# STM32H7P4 register map
File version: 0.1
CPU: CM7 r1p2, little endian, MPU, FPU, 4 interrupt priority bits
Registers are 32-bit, read-write, reset 0x0 unless marked. A register's access mark holds for its fields unless they carry their own. Offsets are from the block's base; [hi:lo] are bit positions.

## ADCC12 — Analog-to-digital converters
Base 0x48026300
Same registers: ADCC34 0x48026700
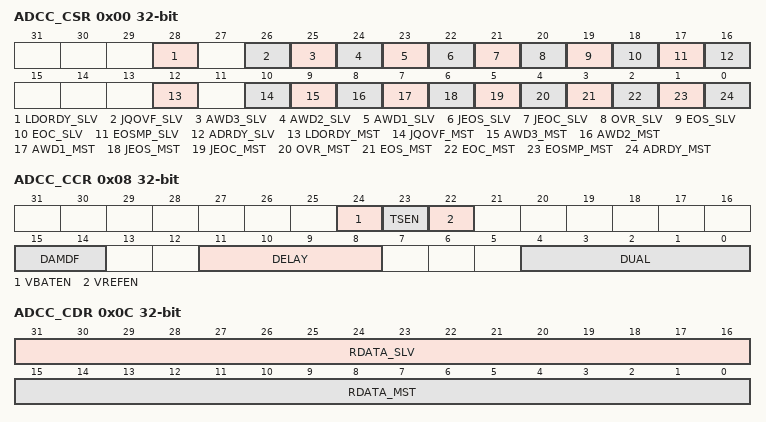
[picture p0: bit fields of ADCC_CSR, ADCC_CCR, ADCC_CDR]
0x00 ADCC_CSR ro — ADC common status register
  [28] LDORDY_SLV — ADC internal voltage regulator flag of the slave ADC
  [26] JQOVF_SLV — Injected context queue overflow flag of the slave ADC
  [25] AWD3_SLV — Analog watchdog 3 flag of the slave ADC
  [24] AWD2_SLV — Analog watchdog 2 flag of the slave ADC
  [23] AWD1_SLV — Analog watchdog 1 flag of the slave ADC
  [22] JEOS_SLV — End of injected sequence flag of the slave ADC
  [21] JEOC_SLV — End of injected conversion flag of the slave ADC
  [20] OVR_SLV — Overrun flag of the slave ADC
  [19] EOS_SLV — End of regular sequence flag of the slave ADC. This bit is a copy of the EOS bit in the corresponding ADC_ISR register.
  [18] EOC_SLV — End of regular conversion of the slave ADC
  [17] EOSMP_SLV — End of sampling phase flag of the slave ADC
  [16] ADRDY_SLV — Slave ADC ready
  [12] LDORDY_MST — ADC internal voltage regulator flag of the master ADC
  [10] JQOVF_MST — Injected context queue overflow flag of the master ADC
  [9] AWD3_MST — Analog watchdog 3 flag of the master ADC
  [8] AWD2_MST — Analog watchdog 2 flag of the master ADC
  [7] AWD1_MST — Analog watchdog 1 flag of the master ADC
  [6] JEOS_MST — End of injected sequence flag of the master ADC
  [5] JEOC_MST — End of injected conversion flag of the master ADC
  [4] OVR_MST — Overrun flag of the master ADC
  [3] EOS_MST — End of regular sequence flag of the master ADC
  [2] EOC_MST — End of regular conversion of the master ADC
  [1] EOSMP_MST — End of Sampling phase flag of the master ADC
  [0] ADRDY_MST — Master ADC ready
0x08 ADCC_CCR — ADC common control register
  [24] VBATEN — VBAT enable
    0=Vless thansub>BATless than/sub> channel disabled; 1=Vless thansub>BATless than/sub> channel enabled
  [23] TSEN — Temperature sensor voltage enable
    0=Temperature sensor channel disabled; 1=Temperature sensor channel enabled
  [22] VREFEN — Vless thansub>REFINTless than/sub> enable
    0=Vless thansub>REFINTless than/sub> channel disabled; 1=Vless thansub>REFINTless than/sub> channel enabled
  [15:14] DAMDF — Dual ADC mode data format
    0=Dual ADC mode without data packing (ADCC_CDR and ADCC_CDR2 registers not used); 2=Data formatting mode for any data width (ADCC_CDR data register is used when the data width is less than 16 bits, otherwise ADCC_CDR2 register is used); 3=Data formatting mode for data width lower that 8 bits (ADCC_CDR data register is used)
  [11:8] DELAY — Delay between two sampling phases
  [4:0] DUAL — Dual ADC mode selection
    0=Independent mode; 1=Combined regular simultaneous + Injected simultaneous mode; 2=Combined regular simultaneous + Alternate trigger mode; 3=Combined interleaved mode + Injected simultaneous mode; 5=Injected simultaneous mode only; 6=Regular simultaneous mode only; 7=Interleaved mode only; 9=Alternate trigger mode only
0x0C ADCC_CDR ro — ADC common regular data register for dual mode
  [31:16] RDATA_SLV — Regular data of the slave ADC
  [15:0] RDATA_MST — Regular data of the master ADC.
0x10 ADCC_CDR2 ro — ADC common regular data register for dual mode
  [31:0] RDATA_ALT — Regular data of the master/slave alternated ADCs.

## COMP — COMP register block
Base 0x58007000
Same registers: COMP34 0x58007400, COMP56 0x58007800, COMP78 0x58007C00
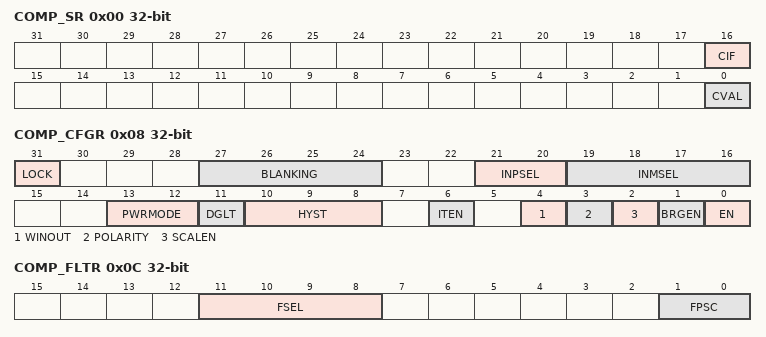
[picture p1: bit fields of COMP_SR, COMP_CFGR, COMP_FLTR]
0x00 COMP_SR ro — Comparator status register
  [16] CIF — COMP interrupt flag
  [0] CVAL — COMP output status bit
0x04 COMP_ICFR reset 0x4 — Comparator interrupt clear flag register
  [16] CCIF — Clear COMP interrupt flag
0x08 COMP_CFGR — Comparator configuration register
  [31] LOCK — Lock bit
    0=COMP_CFGR, COMP_FLTR register is read/write; 1=COMP_CFGR, COMP_FLTR and COMP_OR registers are read-only
  [27:24] BLANKING — COMP channel blanking source selection bits
  [21:20] INPSEL — COMP channel non-inverting input selection bit
  [19:16] INMSEL — COMP channel inverting input selection field
  [13:12] PWRMODE — COMP power mode selector
  [11] DGLT — DEGLITCHER enable
    0=Disable; 1=Enable
  [10:8] HYST — COMP channel hysteresis selection bits
  [6] ITEN — COMP channel interrupt enable
    0=Interrupt generation disabled for COMP channel; 1=Interrupt generation enabled for COMP channel
  [4] WINOUT — COMP output selector
    0=comp_out = comp_value; 1=comp_out = winout (window mode output)
  [3] POLARITY — COMP polarity selection bit
    0=COMP output is not inverted; 1=COMP output is inverted
  [2] SCALEN — Voltage scaler enable bit
    0=comp_int_vref scaler disabled; 1=comp_int_vref scaler enabled
  [1] BRGEN — Scaler bridge enable
    0=comp_int_vref scaler resistor bridge disabled; 1=comp_int_vref scaler resistor bridge enabled
  [0] EN — COMP channel enable bit
    0=Disable; 1=Enable
0x0C COMP_FLTR — Comparator filter configuration register
  [11:8] FSEL — COMP digital filter configuration selection
    0=Filter disabled; 1=filter_sampling = comp_pclk, N = 2; 2=filter_sampling = comp_pclk, N = 4; 3=filter_sampling = comp_pclk, N = 8; 4=filter_sampling = filter_clk/2, N = 6; 5=filter_sampling = filter_clk/2, N = 8; 6=filter_sampling = filter_clk/4, N = 6; 7=filter_sampling = filter_clk/4, N = 8; 8=filter_sampling = filter_clk/8, N = 6; 9=filter_sampling = filter_clk/8, N = 8; 10=filter_sampling = filter_clk/16, N = 5; 11=filter_sampling = filter_clk/16, N = 6; 12=filter_sampling = filter_clk/16, N = 8; 13=filter_sampling = filter_clk/32, N = 5; 14=filter_sampling = filter_clk/32, N = 6; 15=filter_sampling = filter_clk/32, N = 8
  [1:0] FPSC — COMP digital filter configuration selection
    0=filter_clk = comp_pclk; 1=filter_clk = comp_pclk/2; 2=filter_clk = comp_pclk/4; 3=filter_clk = comp_pclk/8
